# STM32U073 register map
File version: 0.2
CPU: CM0+ r0p1, little endian, MPU, no FPU, 4 interrupt priority bits
Registers are 32-bit, read-write, reset 0x0 unless marked. A register's access mark holds for its fields unless they carry their own. Offsets are from the block's base; [hi:lo] are bit positions.

## DBGMCU — DBGMCU register block
Base 0x40015800
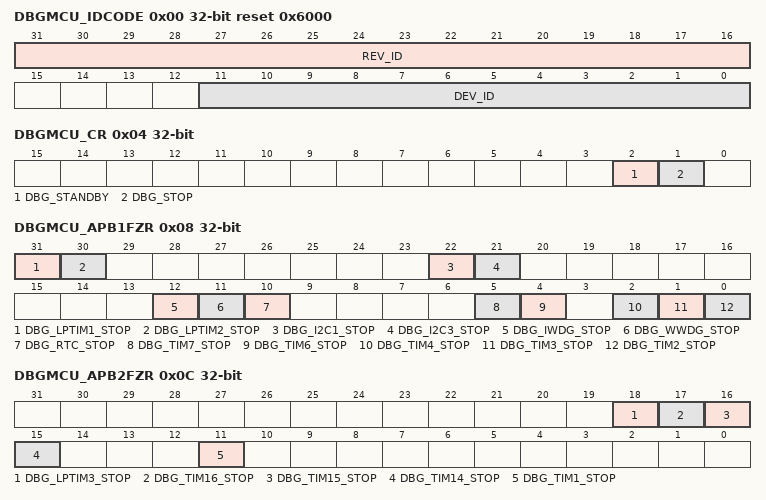
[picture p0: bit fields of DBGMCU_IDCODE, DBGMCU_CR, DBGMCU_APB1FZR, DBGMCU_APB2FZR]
0x00 DBGMCU_IDCODE ro reset 0x6000 (reset mask 0xF000) — DBGMCU device ID code register
  [31:16] REV_ID — Revision identifier This field indicates the revision of the device.
    0x1000=Revision A for STM32U031/73/83xx
  [11:0] DEV_ID — Device identifier This field indicates the device ID.
    0x459=STM32U031xx; 0x489=STM32U073/083xx
0x04 DBGMCU_CR — DBGMCU configuration register
  [2] DBG_STANDBY — Debug Standby and Shutdown modes Debug options in Standby or Shutdown mode.
    0=Digital part powered. From software point of view, exiting Standby and Shutdown modes is identical as fetching reset vector (except for status bits indicating that the MCU exits Standby); 1=Digital part powered and FCLK and HCLK running, derived from the internal RC oscillator remaining active. The MCU generates a system reset so that exiting Standby and Shutdown has the same effect as starting from reset.
  [1] DBG_STOP — Debug Stop mode Debug options in Stop mode.
    0=All clocks disabled, including FCLK and HCLK. Upon Stop mode exit, the CPU is clocked by the HSI internal RC oscillator.; 1=FCLK and HCLK running, derived from the internal RC oscillator remaining active. If SysTick is enabled, it may generate periodic interrupt and wake up events.Upon Stop mode exit, the software must re-establish the desired clock configuration.
0x08 DBGMCU_APB1FZR — DBGMCU APB1 freeze register
  [31] DBG_LPTIM1_STOP — LPTIM1 stop in debug
    0=normal operation. LPTIM1 continues to operate while CPU is in debug mode.; 1=stop in debug. LPTIM1 is frozen while CPU is in debug mode.
  [30] DBG_LPTIM2_STOP — LPTIM2 stop in debug
    0=normal operation. LPTIM2 continues to operate while CPU is in debug mode.; 1=stop in debug. LPTIM2 is frozen while CPU is in debug mode.
  [22] DBG_I2C1_STOP — I2C1 SMBUS timeout stop in debug
    0=normal operation. I2C1 SMBUS timeout continues to operate while CPU is in debug mode.; 1=stop in debug. I2C1 SMBUS timeout is frozen while CPU is in debug mode.
  [21] DBG_I2C3_STOP — I2C3 SMBUS timeout stop in debug
    0=normal operation. I2C3 SMBUS timeout continues to operate while CPU is in debug mode.; 1=stop in debug. I2C3 SMBUS timeout is frozen while CPU is in debug mode.
  [12] DBG_IWDG_STOP — IWDG stop in debug
    0=normal operation. IWDG continues to operate while CPU is in debug mode.; 1=stop in debug. IWDG is frozen while CPU is in debug mode.
  [11] DBG_WWDG_STOP — WWDG stop in debug
    0=normal operation. WWDG continues to operate while CPU is in debug mode.; 1=stop in debug. WWDG is frozen while CPU is in debug mode.
  [10] DBG_RTC_STOP — RTC stop in debug
    0=normal operation. RTC counter continues to operate while CPU is in debug mode.; 1=stop in debug. RTC counter is frozen while CPU is in debug mode.
  [5] DBG_TIM7_STOP — TIM7 stop in debug
    0=normal operation. TIM7 continues to operate while CPU is in debug mode.; 1=stop in debug. TIM7 is frozen while CPU is in debug mode.
  [4] DBG_TIM6_STOP — TIM6 stop in debug
    0=normal operation. TIM6 continues to operate while CPU is in debug mode.; 1=stop in debug. TIM6 is frozen while CPU is in debug mode.
  [2] DBG_TIM4_STOP — TIM4 stop in debug
    0=normal operation. TIM4 continues to operate while CPU is in debug mode.; 1=stop in debug. TIM34 is frozen while CPU is in debug mode
  [1] DBG_TIM3_STOP — TIM3 stop in debug
    0=normal operation. TIM3 continues to operate while CPU is in debug mode.; 1=stop in debug. TIM3 is frozen while CPU is in debug mode.
  [0] DBG_TIM2_STOP — TIM2 stop in debug
    0=normal operation. TIM2 continues to operate while CPU is in debug mode.; 1=stop in debug. TIM2 is frozen while CPU is in debug mode.
0x0C DBGMCU_APB2FZR — DBG APB2 freeze register
  [18] DBG_LPTIM3_STOP — LPTIM3 stop in debug
    0=normal operation. LPTIM3 continues to operate while CPU is in debug mode.; 1=stop in debug. LPTIM3 is frozen while CPU is in debug mode.
  [17] DBG_TIM16_STOP — TIM16 stop in debug
    0=normal operation. TIM16 continues to operate while CPU is in debug mode.; 1=stop in debug. TIM16 is frozen while CPU is in debug mode.
  [16] DBG_TIM15_STOP — TIM15 stop in debug
    0=normal operation. TIM15 continues to operate while CPU is in debug mode.; 1=stop in debug. TIM15 is frozen while CPU is in debug mode.
  [15] DBG_TIM14_STOP — TIM14 stop in debug
    0=normal operation. TIM14 continues to operate while CPU is in debug mode.; 1=stop in debug. TIM14 is frozen while CPU is in debug mode.
  [11] DBG_TIM1_STOP — TIM1 stop in debug
    0=normal operation. TIM1 continues to operate while CPU is in debug mode.; 1=stop in debug. TIM1 is frozen while CPU is in debug mode.
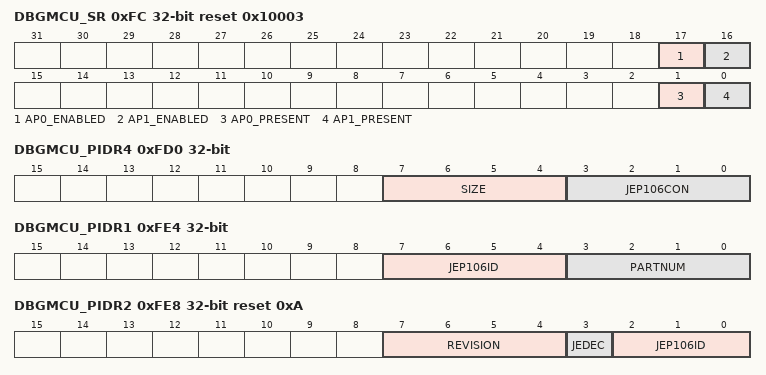
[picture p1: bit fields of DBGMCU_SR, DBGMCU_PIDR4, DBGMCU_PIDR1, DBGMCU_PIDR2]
0xFC DBGMCU_SR ro reset 0x10003 — DBGMCU status register
  [17] AP0_ENABLED — Identifies whether access port AP0 is open (can be accessed via the debug port) or locked (debug access to the AP is blocked)
    0=AP0 locked; 1=AP0 enabled
  [16] AP1_ENABLED — Identifies whether access port AP0 is open (can be accessed via the debug port) or locked (debug access to the AP is blocked)
    0=AP1 locked; 1=AP1 enabled
  [1] AP0_PRESENT — Identifies whether access port AP0 is present in device
    1=AP0 present
  [0] AP1_PRESENT — Identifies whether access port AP1 is present in device
    1=AP1 present
0x100 DBGMCU_DBG_AUTH_HOST reset not defined — DBGMCU debug authentication mailbox host register
  [31:0] MESSAGE — Debug host to device mailbox message. During debug authentication the debug host communicates with the device via this register.
0x104 DBGMCU_DBG_AUTH_DEVICE ro reset not defined — DBGMCU debug authentication mailbox device register
  [31:0] MESSAGE — Device to debug host mailbox message. During debug authentication the device communicates with the debug host via this register.
0xFD0 DBGMCU_PIDR4 ro — DBGMCU CoreSight peripheral identity register 4
  [7:4] SIZE — register file size
    0=The register file occupies a single 4-Kbyte region
  [3:0] JEP106CON — JEP106 continuation code
    0=STMicroelectronics JEDEC code
0xFE0 DBGMCU_PIDR0 ro — DBGMCU CoreSight peripheral identity register 0
  [7:0] PARTNUM — part number bits [7:0]
    0=DBGMCU part number
0xFE4 DBGMCU_PIDR1 ro — DBGMCU CoreSight peripheral identity register 1
  [7:4] JEP106ID — JEP106 identity code bits [3:0]
    0=STMicroelectronics JEDEC code
  [3:0] PARTNUM — part number bits [11:8]
    0=DBGMCU part number
0xFE8 DBGMCU_PIDR2 ro reset 0xA — DBGMCU CoreSight peripheral identity register 2
  [7:4] REVISION — component revision number
    0=r0p0
  [3] JEDEC — JEDEC assigned value
    1=designer identification specified by JEDEC
  [2:0] JEP106ID — JEP106 identity code bits [6:4]
    2=STMicroelectronics JEDEC code
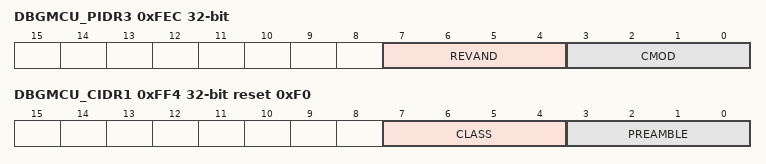
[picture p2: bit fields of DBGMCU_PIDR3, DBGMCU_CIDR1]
0xFEC DBGMCU_PIDR3 ro — DBGMCU CoreSight peripheral identity register 3
  [7:4] REVAND — metal fix version
    0=no metal fix
  [3:0] CMOD — customer modified
    0=no customer modifications
0xFF0 DBGMCU_CIDR0 ro reset 0xD — DBGMCU CoreSight component identity register 0
  [7:0] PREAMBLE — component identification bits [7:0]
    13=common identification value
0xFF4 DBGMCU_CIDR1 ro reset 0xF0 — DBGMCU CoreSight component identity register 1
  [7:4] CLASS — component identification bits [15:12] - component class
    15=Non-CoreSight component
  [3:0] PREAMBLE — component identification bits [11:8]
    0=common identification value
0xFF8 DBGMCU_CIDR2 ro reset 0x5 — DBGMCU CoreSight component identity register 2
  [7:0] PREAMBLE — component identification bits [23:16]
    5=common identification value
0xFFC DBGMCU_CIDR3 ro reset 0xB1 — DBGMCU CoreSight component identity register 3
  [7:0] PREAMBLE — component identification bits [31:24]
    177=common identification value
